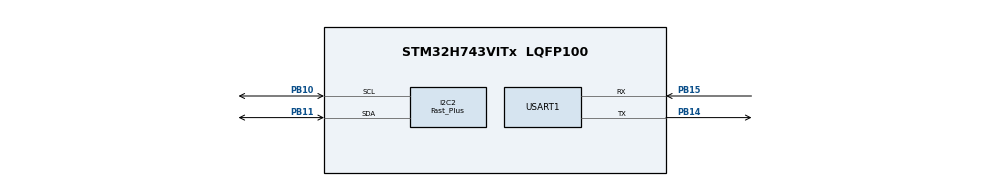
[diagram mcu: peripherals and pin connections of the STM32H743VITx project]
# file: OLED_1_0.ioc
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Dma.I2C2_TX.0.Direction=DMA_MEMORY_TO_PERIPH
Dma.I2C2_TX.0.EventEnable=DISABLE
Dma.I2C2_TX.0.FIFOMode=DMA_FIFOMODE_DISABLE
Dma.I2C2_TX.0.Instance=DMA1_Stream0
Dma.I2C2_TX.0.MemDataAlignment=DMA_MDATAALIGN_BYTE
Dma.I2C2_TX.0.MemInc=DMA_MINC_ENABLE
Dma.I2C2_TX.0.Mode=DMA_NORMAL
Dma.I2C2_TX.0.PeriphDataAlignment=DMA_PDATAALIGN_BYTE
Dma.I2C2_TX.0.PeriphInc=DMA_PINC_DISABLE
Dma.I2C2_TX.0.Polarity=HAL_DMAMUX_REQ_GEN_RISING
Dma.I2C2_TX.0.Priority=DMA_PRIORITY_LOW
Dma.I2C2_TX.0.RequestNumber=1
Dma.I2C2_TX.0.SignalID=NONE
Dma.I2C2_TX.0.SyncEnable=DISABLE
Dma.I2C2_TX.0.SyncPolarity=HAL_DMAMUX_SYNC_NO_EVENT
Dma.I2C2_TX.0.SyncRequestNumber=1
Dma.I2C2_TX.0.SyncSignalID=NONE
Dma.Request0=I2C2_TX
I2C2.I2C_Speed_Mode=I2C_Fast_Plus
I2C2.Timing=0x0050174F
Mcu.Family=STM32H7
Mcu.Name=STM32H743VITx
Mcu.Package=LQFP100
NVIC.DMA1_Stream0_IRQn=true\:0\:0\:false\:false\:true\:false\:true\:true
NVIC.I2C2_ER_IRQn=true\:0\:0\:false\:false\:true\:true\:true\:true
NVIC.I2C2_EV_IRQn=true\:0\:0\:false\:false\:true\:true\:true\:true
NVIC.PriorityGroup=NVIC_PRIORITYGROUP_4
NVIC.USART1_IRQn=true\:0\:0\:false\:false\:true\:true\:true\:true
PB10.Mode=I2C
PB10.Signal=I2C2_SCL
PB11.Mode=I2C
PB11.Signal=I2C2_SDA
PB14.Mode=Asynchronous
PB14.Signal=USART1_TX
PB15.Mode=Asynchronous
PB15.Signal=USART1_RX
PC14-OSC32_IN\ (OSC32_IN).Mode=LSE-External-Oscillator
PC14-OSC32_IN\ (OSC32_IN).Signal=RCC_OSC32_IN
PC15-OSC32_OUT\ (OSC32_OUT).Mode=LSE-External-Oscillator
PC15-OSC32_OUT\ (OSC32_OUT).Signal=RCC_OSC32_OUT
PH0-OSC_IN\ (PH0).Mode=HSE-External-Oscillator
PH0-OSC_IN\ (PH0).Signal=RCC_OSC_IN
PH1-OSC_OUT\ (PH1).Mode=HSE-External-Oscillator
PH1-OSC_OUT\ (PH1).Signal=RCC_OSC_OUT
ProjectManager.HeapSize=0x200
ProjectManager.StackSize=0x400
ProjectManager.TargetToolchain=MDK-ARM V5.27
RCC.ADCFreq_Value=50390625
RCC.APB1Freq_Value=120000000
RCC.APB2Freq_Value=120000000
RCC.APB3Freq_Value=120000000
RCC.APB4Freq_Value=120000000
RCC.CortexFreq_Value=480000000
RCC.D1PPRE=RCC_APB3_DIV2
RCC.D2PPRE1=RCC_APB1_DIV2
RCC.D2PPRE2=RCC_APB2_DIV2
RCC.D3PPRE=RCC_APB4_DIV2
RCC.DIVM1=5
RCC.DIVN1=192
RCC.HCLKFreq_Value=240000000
RCC.HPRE=RCC_HCLK_DIV2
RCC.PLLSourceVirtual=RCC_PLLSOURCE_HSE
RCC.SYSCLKFreq_VALUE=480000000
RCC.SYSCLKSource=RCC_SYSCLKSOURCE_PLLCLK
RCC.USBFreq_Value=480000000
USART1.VirtualMode-Asynchronous=VM_ASYNC
board=custom

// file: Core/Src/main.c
/* USER CODE BEGIN Header */
/**
  ******************************************************************************
  * @file           : main.c
  * @brief          : Main program body
  ******************************************************************************
  * @attention
  *
  * Copyright (c) 2025 STMicroelectronics.
  * All rights reserved.
  *
  * This software is licensed under terms that can be found in the LICENSE file
  * in the root directory of this software component.
  * If no LICENSE file comes with this software, it is provided AS-IS.
  *
  ******************************************************************************
  */
/* USER CODE END Header */
#include "main.h"
#include "dma.h"
#include "i2c.h"
#include "usart.h"
#include "gpio.h"

/* USER CODE BEGIN Includes */
#include "OLED.h"
/* USER CODE END Includes */

void SystemClock_Config(void);

int main(void)
{

  /* MCU Configuration--------------------------------------------------------*/

  /* Reset of all peripherals, Initializes the Flash interface and the Systick. */
  HAL_Init();

  /* Configure the system clock */
  SystemClock_Config();

  /* Initialize all configured peripherals */
  MX_GPIO_Init();
  MX_DMA_Init();
  MX_I2C2_Init();
  MX_USART1_UART_Init();
  /* USER CODE BEGIN 2 */
	OLED_Init();
	OLED_Test();
	OLED_Update();
	HAL_Delay(100);
	OLED_Clear();

	Test_Jiangxie1();

  /* USER CODE END 2 */

  /* Infinite loop */
  while (1)
  {

    /* USER CODE BEGIN 3 */
		//Frame_Test();
		Test_JiangXie2();
	}

  /* USER CODE END 3 */
}

void SystemClock_Config(void)
{
  RCC_OscInitTypeDef RCC_OscInitStruct = {0};
  RCC_ClkInitTypeDef RCC_ClkInitStruct = {0};

  /** Supply configuration update enable
  */
  HAL_PWREx_ConfigSupply(PWR_LDO_SUPPLY);

  /** Configure the main internal regulator output voltage
  */
  __HAL_PWR_VOLTAGESCALING_CONFIG(PWR_REGULATOR_VOLTAGE_SCALE1);

  while(!__HAL_PWR_GET_FLAG(PWR_FLAG_VOSRDY)) {}

  __HAL_RCC_SYSCFG_CLK_ENABLE();
  __HAL_PWR_VOLTAGESCALING_CONFIG(PWR_REGULATOR_VOLTAGE_SCALE0);

  while(!__HAL_PWR_GET_FLAG(PWR_FLAG_VOSRDY)) {}

  /** Initializes the RCC Oscillators according to the specified parameters
  * in the RCC_OscInitTypeDef structure.
  */
  RCC_OscInitStruct.OscillatorType = RCC_OSCILLATORTYPE_HSE;
  RCC_OscInitStruct.HSEState = RCC_HSE_ON;
  RCC_OscInitStruct.PLL.PLLState = RCC_PLL_ON;
  RCC_OscInitStruct.PLL.PLLSource = RCC_PLLSOURCE_HSE;
  RCC_OscInitStruct.PLL.PLLM = 5;
  RCC_OscInitStruct.PLL.PLLN = 192;
  RCC_OscInitStruct.PLL.PLLP = 2;
  RCC_OscInitStruct.PLL.PLLQ = 2;
  RCC_OscInitStruct.PLL.PLLR = 2;
  RCC_OscInitStruct.PLL.PLLRGE = RCC_PLL1VCIRANGE_2;
  RCC_OscInitStruct.PLL.PLLVCOSEL = RCC_PLL1VCOWIDE;
  RCC_OscInitStruct.PLL.PLLFRACN = 0;
  if (HAL_RCC_OscConfig(&RCC_OscInitStruct) != HAL_OK)
  {
    Error_Handler();
  }

  /** Initializes the CPU, AHB and APB buses clocks
  */
  RCC_ClkInitStruct.ClockType = RCC_CLOCKTYPE_HCLK|RCC_CLOCKTYPE_SYSCLK
                              |RCC_CLOCKTYPE_PCLK1|RCC_CLOCKTYPE_PCLK2
                              |RCC_CLOCKTYPE_D3PCLK1|RCC_CLOCKTYPE_D1PCLK1;
  RCC_ClkInitStruct.SYSCLKSource = RCC_SYSCLKSOURCE_PLLCLK;
  RCC_ClkInitStruct.SYSCLKDivider = RCC_SYSCLK_DIV1;
  RCC_ClkInitStruct.AHBCLKDivider = RCC_HCLK_DIV2;
  RCC_ClkInitStruct.APB3CLKDivider = RCC_APB3_DIV2;
  RCC_ClkInitStruct.APB1CLKDivider = RCC_APB1_DIV2;
  RCC_ClkInitStruct.APB2CLKDivider = RCC_APB2_DIV2;
  RCC_ClkInitStruct.APB4CLKDivider = RCC_APB4_DIV2;

  if (HAL_RCC_ClockConfig(&RCC_ClkInitStruct, FLASH_LATENCY_4) != HAL_OK)
  {
    Error_Handler();
  }
}

void Error_Handler(void)
{
  __disable_irq();
  while (1)
  {
  }
}
